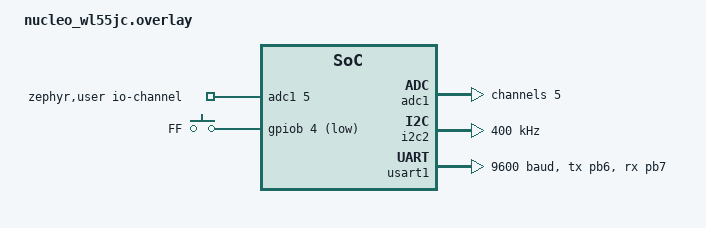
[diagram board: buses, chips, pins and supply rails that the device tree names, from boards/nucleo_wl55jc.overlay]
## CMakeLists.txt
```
# SPDX-License-Identifier: Apache-2.0

cmake_minimum_required(VERSION 3.20.0)
find_package(Zephyr REQUIRED HINTS $ENV{ZEPHYR_BASE})
project(MultiSensorPPE)

FILE(GLOB app_sources src/*.c)
target_sources(app PRIVATE ${app_sources})
```

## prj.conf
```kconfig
# General system configuration
CONFIG_MAIN_STACK_SIZE=2048
CONFIG_SYSTEM_WORKQUEUE_STACK_SIZE=2048
CONFIG_ASSERT=y
CONFIG_THREAD_NAME=y

# Logging and debugging
CONFIG_LOG=y
CONFIG_LOG_DEFAULT_LEVEL=3
CONFIG_STDOUT_CONSOLE=y
CONFIG_CBPRINTF_FP_SUPPORT=y

# Device drivers
CONFIG_GPIO=y
CONFIG_ADC=y
CONFIG_I2C=y
CONFIG_SENSOR=y
CONFIG_FLASH=y
CONFIG_FLASH_MAP=y
CONFIG_FLASH_PAGE_LAYOUT=y
CONFIG_STREAM_FLASH=y
CONFIG_IMG_MANAGER=y

# UART configuration
CONFIG_UART_ASYNC_API=y
CONFIG_UART_INTERRUPT_DRIVEN=y

# LoRa and LoRaWAN configuration
CONFIG_LORA=y
CONFIG_LORAWAN=y
CONFIG_LORAMAC_REGION_EU868=y
CONFIG_LORAWAN_NVM_SETTINGS=y  # Use NVM to store OTAA parameters
CONFIG_ENTROPY_GENERATOR=y  # Entropy source

# Non-volatile storage (NVS)
CONFIG_NVS=y
CONFIG_SETTINGS=y  # Required to store LoRaWAN DevNonce and other settings

# Zephyr Bus configuration
CONFIG_ZBUS=y
CONFIG_ZBUS_CHANNEL_NAME=y
```

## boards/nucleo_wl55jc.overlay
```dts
/*
 * SPDX-License-Identifier: Apache-2.0
 *
 * Copyright (c) 2022 QRTECH
 */

/ {
	zephyr,user {
		io-channels = <&adc1 5>;
	};

	gpio_keys {
		compatible = "gpio-keys";

		accel_interrup: adc_in1_pb4 {
			label = "FF";
			gpios = <&gpiob 4 (GPIO_ACTIVE_LOW | GPIO_PULL_UP)>;
			zephyr,code = <INPUT_KEY_3>;
		};
	};

	aliases {
		ff0 = &accel_interrup;
	};

};

&adc1 {
	#address-cells = <1>;
	#size-cells = <0>;

	channel@5 {
		reg = <5>;
		zephyr,gain = "ADC_GAIN_1";
		zephyr,reference = "ADC_REF_INTERNAL";
		zephyr,acquisition-time = <ADC_ACQ_TIME_DEFAULT>;
		zephyr,resolution = <12>;
	};
};

&i2c2 {
    status = "okay";
    clock-frequency = <I2C_BITRATE_FAST>; // 400kHz
};

&usart1 {
	dmas = <&dmamux1 11 18 (STM32_DMA_PERIPH_TX | STM32_DMA_PRIORITY_HIGH)
		&dmamux1 1 17 (STM32_DMA_PERIPH_RX | STM32_DMA_PRIORITY_HIGH)>;
	dma-names = "tx", "rx";
	pinctrl-0 = <&usart1_tx_pb6 &usart1_rx_pb7>;
	pinctrl-names = "default";
	current-speed = <9600>;
	status = "okay";
};

&dma1 {
	status = "okay";
};

&dma2 {
	status = "okay";
};

&dmamux1 {
	status = "okay";
};

&gpiob {
    status = "okay";
};
```

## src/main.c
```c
#include <zephyr/kernel.h>
#include <zephyr/device.h>
#include <zephyr/logging/log.h>
#include <zephyr/drivers/gpio.h>
#include <zephyr/sys/util.h>
#include <zephyr/sys/printk.h>
#include <inttypes.h>
#include <zephyr/sys/util_macro.h>
#include <zephyr/zbus/zbus.h>

#include "messages.h"
#include "gps_sensor.h"

LOG_MODULE_REGISTER(main, LOG_LEVEL_INF);

#define USART_NODE DT_NODELABEL(usart1)
#if !DT_NODE_HAS_STATUS_OKAY(USART_NODE)
#error "Unsupported board: usart1 devicetree node label is not defined"
#endif
#define FF_INT DT_ALIAS(ff0)
#if !DT_NODE_HAS_STATUS_OKAY(FF_INT)
#error "Unsupported board: ffpin devicetree alias is not defined"
#endif
#define SW0_NODE DT_ALIAS(sw1)
#if !DT_NODE_HAS_STATUS_OKAY(SW0_NODE)
#error "Unsupported board: sw1 devicetree alias is not defined"
#endif
#define SWSOS_NODE DT_ALIAS(sw2)
#if !DT_NODE_HAS_STATUS_OKAY(SWSOS_NODE)
#error "Unsupported board: sw2 devicetree alias is not defined"
#endif

#define PERIODIC_SENSOR_TIME    K_SECONDS(30)
#define LONG_PRESS_TIME    K_MSEC(2000)
#define SOS_LONG_PRESS_TIME    K_MSEC(1000)

ZBUS_CHAN_DECLARE(events_chan);
ZBUS_CHAN_DECLARE(sensor_data_chan);

static const struct device *usart_dev = DEVICE_DT_GET(USART_NODE);
static const struct gpio_dt_spec freefall = GPIO_DT_SPEC_GET_OR(FF_INT, gpios, {0});
static const struct gpio_dt_spec button = GPIO_DT_SPEC_GET_OR(SW0_NODE, gpios, {0});
static const struct gpio_dt_spec sos_button = GPIO_DT_SPEC_GET_OR(SWSOS_NODE, gpios, {0});
static struct gpio_callback freefall_cb_data;
static struct gpio_callback button_cb_data;
static struct gpio_callback sos_button_cb_data;

static uint8_t button_pressed = 0;
static uint8_t sos_button_pressed = 0;

struct events_wq_info {
	struct k_work work;
	const struct zbus_channel *chan;
	uint8_t handle;
};

static struct events_wq_info wq_button_event_handler = {.chan = &events_chan, .handle = 1};
static struct events_wq_info wq_sos_button_event_handler = {.chan = &events_chan, .handle = 2};
static struct events_wq_info wq_freefall_event_handler = {.chan = &events_chan, .handle = 3};
static struct events_wq_info wq_timer_event_handler = {.chan = &events_chan, .handle = 4};

void freefall_detect(const struct device *dev, struct gpio_callback *cb, uint32_t pins) {
    k_work_submit(&wq_freefall_event_handler.work);
}

void sos_button_timeout_handler(struct k_timer *timer_id) {
    if (sos_button_pressed) {
        sos_button_pressed = 0;
        k_work_submit(&wq_sos_button_event_handler.work);
    }
}

K_TIMER_DEFINE(sos_button_timer, sos_button_timeout_handler, NULL);

void sos_button_pressed_handler(const struct device *dev, struct gpio_callback *cb, uint32_t pins) {
    int val = gpio_pin_get(dev, sos_button.pin);

    if (val == 0) { // Button released
        sos_button_pressed = 0;
    } else { //Button Pressed
        sos_button_pressed = 1;
        k_timer_start(&sos_button_timer, SOS_LONG_PRESS_TIME, K_FOREVER);
    }
}

void button_timeout_handler(struct k_timer *timer_id) {
    if (button_pressed) {
        button_pressed = 0;
        k_work_submit(&wq_button_event_handler.work);
    }
} 

K_TIMER_DEFINE(button_timer, button_timeout_handler, NULL);

void button_pressed_handler(const struct device *dev, struct gpio_callback *cb, uint32_t pins) {
    int val = gpio_pin_get(dev, button.pin);

    if (val == 0) { // Button released
        button_pressed = 0;
    } else { //Button Pressed
        button_pressed = 1;
        k_timer_start(&button_timer, LONG_PRESS_TIME, K_FOREVER);
    }
}

static void wq_eh_cb(struct k_work *item)
{
	struct events_wq_info *sens = CONTAINER_OF(item, struct events_wq_info, work);
    uint8_t msg = sens->handle;
    zbus_chan_pub(&events_chan, &msg, K_MSEC(250));

	LOG_INF("Event_handler %u", sens->handle);
}

static void timer_cb (struct k_timer *timer_id) {
    k_work_submit(&wq_timer_event_handler.work);
}

K_TIMER_DEFINE(event_timer, timer_cb, NULL);

int main(void)
{

    if (!gpio_is_ready_dt(&button))
        LOG_ERR("Error button device is not ready");
    if (gpio_pin_configure_dt(&button, GPIO_INPUT))
        LOG_ERR("Error failed to configure pin");
    if (gpio_pin_interrupt_configure_dt(&button, GPIO_INT_EDGE_BOTH)) 
        LOG_ERR("Error failed to configure interrupt on pin");
    
    gpio_init_callback(&button_cb_data, button_pressed_handler, BIT(button.pin));
    gpio_add_callback(button.port, &button_cb_data);

    LOG_INF("Set up %s pin %d as Button Interuption Pin Succesfully", button.port->name, button.pin);

    if (!gpio_is_ready_dt(&sos_button))
        LOG_ERR("Error sos_button device is not ready");
    if (gpio_pin_configure_dt(&sos_button, GPIO_INPUT))
        LOG_ERR("Error failed to configure pin");
    if (gpio_pin_interrupt_configure_dt(&sos_button, GPIO_INT_EDGE_FALLING)) 
        LOG_ERR("Error failed to configure interrupt on pin");
    
    gpio_init_callback(&sos_button_cb_data, sos_button_pressed_handler, BIT(sos_button.pin));
    gpio_add_callback(sos_button.port, &sos_button_cb_data);

    LOG_INF("Set up %s pin %d as SOS Button Interuption Pin Succesfully", sos_button.port->name, sos_button.pin);

    if (!gpio_is_ready_dt(&freefall))
        LOG_ERR("Error freefall pin %s is not ready", freefall.port->name);
    if (gpio_pin_configure_dt(&freefall, GPIO_INPUT))
        LOG_ERR("Error failed to configure FREEFALL pin");
    if (gpio_pin_interrupt_configure_dt(&freefall, GPIO_INT_EDGE_FALLING))
        LOG_ERR("Error failed to configure interrupt on FREEFALL pin");

    gpio_init_callback(&freefall_cb_data, freefall_detect, BIT(freefall.pin));
    gpio_add_callback(freefall.port, &freefall_cb_data);

    LOG_INF("Set up %s pin %d as FreeFall Interruption Pin Succesfully", freefall.port->name, freefall.pin);

    usart1_capture(usart_dev);
    
    k_work_init(&wq_timer_event_handler.work, wq_eh_cb);
    k_work_init(&wq_freefall_event_handler.work, wq_eh_cb);
    k_work_init(&wq_button_event_handler.work, wq_eh_cb);
    k_work_init(&wq_sos_button_event_handler.work, wq_eh_cb);
    k_timer_start(&event_timer, PERIODIC_SENSOR_TIME, PERIODIC_SENSOR_TIME);

    return 0;
    
}
```

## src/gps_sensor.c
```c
#include <zephyr/kernel.h>
#include <zephyr/device.h>
#include <zephyr/drivers/uart.h>
#include <zephyr/logging/log.h>
#include <string.h>
#include <stdlib.h>

LOG_MODULE_REGISTER(gps_parser, LOG_LEVEL_INF); 

#define UART_BUFFER_SIZE 128
#define GPS_BUFFER_SIZE 80 

static const struct device *uart_dev;
static uint8_t recv_buffer[UART_BUFFER_SIZE];
static uint8_t gps_buffer[GPS_BUFFER_SIZE];
static size_t recv_index = 0;
static bool capturing = false;

static const char gpgga_prefix[] = "$GPGGA";
// Estructura para almacenar datos del GPS
typedef struct
{
    float latitude;
    char lat_dir; // N o S o M
    float longitude;
    char lon_dir; // E o O
    uint8_t fix_indicator; // 0 Fix no disponible 1 Fix 2 Diferential fix
    //int num_satellites;
    float altitude;
} gps_data_t;

static gps_data_t current_gps_data;

// Función para parsear sentencia GPGGA
void parse_gpgga(const char *nmea_sentence, gps_data_t *gps_data)
{
    char *token;
    char sentence_copy[UART_BUFFER_SIZE]; // Buffer copia auxiliar
    strncpy(sentence_copy, nmea_sentence, UART_BUFFER_SIZE - 1);
    sentence_copy[UART_BUFFER_SIZE - 1] = '\0'; // Fijamos valor final

    // Eliminar el checksum al final si está presente
    char *checksum_start = strchr(sentence_copy, '*');
    if (checksum_start)
    {
        *checksum_start = '\0';
    }

    // Omitir "$GPGGA" - Ignoramos
    token = strtok(sentence_copy, ","); // "$GPGGA"

    // 1. Time - Ignoramos
    token = strtok(NULL, ",");

    // 2. Latitud valor
    token = strtok(NULL, ",");
    if (token && strlen(token) > 0)
    {
        gps_data->latitude = atof(token);
    }
    else
    {
        gps_data->latitude = 0.0;
    }

    // 3. Latitud
    token = strtok(NULL, ",");
    if (token && strlen(token) > 0)
    {
        gps_data->lat_dir = token[0];
    }
    else
    {
        gps_data->lat_dir = ' ';
    }

    // 4. Longitud valor
    token = strtok(NULL, ",");
    if (token && strlen(token) > 0)
    {
        gps_data->longitude = atof(token);
    }
    else
    {
        gps_data->longitude = 0.0;
    }

    // 5. Longitud
    token = strtok(NULL, ",");
    if (token && strlen(token) > 0)
    {
        gps_data->lon_dir = token[0];
    }
    else
    {
        gps_data->lon_dir = ' ';
    }

    // 6. Fix Indicator
    token = strtok(NULL, ",");
    if (token && strlen(token) > 0)
    {
        gps_data->fix_indicator = atoi(token);
    }
    else
    {
        gps_data->fix_indicator = 0;
    }

    // 7. Number of Satellites - Ignoramos
    token = strtok(NULL, ",");
    

    // 8. HDOP - Ignoramos
    token = strtok(NULL, ",");

    // 9. Altitud
    token = strtok(NULL, ",");
    if (token && strlen(token) > 0)
    {
        gps_data->altitude = atof(token);
    }
    else
    {
        gps_data->altitude = 0.0;
    }
}

static void uart_cb(const struct device *dev, struct uart_event *evt, void *user_data)
{
    ARG_UNUSED(dev);
    ARG_UNUSED(user_data);

    switch (evt->type)
    {
        case UART_RX_RDY:
        for (int i = 0; i < evt->data.rx.len; i++)
        {
            char c = evt->data.rx.buf[evt->data.rx.offset + i];

            // Buscamos Inicio Sentencia %GPGGA
            if (!capturing)
            {
                // Desplazamiento de ventana para comparar con "$GPGGA"
                // Un pequeño buffer estático para detectar el prefijo
                static char window[6] = {0};
                for (int j = 0; j < 5; j++)
                {
                    window[j] = window[j + 1];
                }
                window[5] = c;

                if (strncmp(window, gpgga_prefix, 6) == 0)
                {
                    capturing = true;
                    recv_index = 0;
                    memcpy(gps_buffer, gpgga_prefix, 6);
                    recv_index = 6;
                }
            }
            else
            {
                // Captura $GPGGA hasta \n
                if (recv_index < UART_BUFFER_SIZE - 1)
                {
                    gps_buffer[recv_index++] = c;

                    if (c == '\n')
                    {
                        gps_buffer[recv_index] = '\0';

                        parse_gpgga((char *)gps_buffer, &current_gps_data);
                        capturing = false;
                        recv_index = 0;
                    }
                }
                else
                {
                    capturing = false;
                    recv_index = 0;
                }
            }
        }
        break;

    case UART_RX_DISABLED:
        memset(gps_buffer,0,GPS_BUFFER_SIZE);
        break;

    case UART_RX_BUF_REQUEST:
        uart_rx_buf_rsp(dev, gps_buffer, GPS_BUFFER_SIZE);
        break;
    default:
        break;
    }
}

int usart1_capture(const struct device *uart_dev)
{

    if (!device_is_ready(uart_dev))
    {
        LOG_ERR("UART device not ready");
        return -ENODEV;
    }

    uart_callback_set(uart_dev, uart_cb, NULL);

    int err = uart_rx_enable(uart_dev, recv_buffer, UART_BUFFER_SIZE, SYS_FOREVER_US);
    if (err)
    {
        LOG_ERR("Failed to enable UART RX: %d", err);
        return err;
    }

    LOG_INF("USART GPS listener succesfully started");

    current_gps_data.latitude = 0.0f;
    current_gps_data.lat_dir = " ";
    current_gps_data.longitude = 0.0f;
    current_gps_data.lon_dir = " ";
    current_gps_data.fix_indicator = 0;
    current_gps_data.altitude = 0.0f;
    return 0;
}

float readLatitude(void){ return current_gps_data.latitude; }
char readLatitudeDirection(void){ return current_gps_data.lat_dir; }
float readLongitude(void){ return current_gps_data.longitude; }
float readLLongitudeDirection(void){ return current_gps_data.lon_dir; }
uint8_t readFixIndicator(void){ return current_gps_data.fix_indicator; }
float readAltitude (void) { return current_gps_data.altitude; }
```

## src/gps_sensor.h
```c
#pragma once

#include <zephyr/device.h>

int usart1_capture(const struct device *uart_dev);
float readLatitude(void);
char readLatitudeDirection(void);
float readLongitude(void);
float readLLongitudeDirection(void);
uint8_t readFixIndicator(void);
float readAltitude (void);
```

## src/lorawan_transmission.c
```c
#include <zephyr/kernel.h>
#include <zephyr/device.h>
#include <zephyr/logging/log.h>
#include <zephyr/zbus/zbus.h>
#include <zephyr/lorawan/lorawan.h>

#include "messages.h"

#define LORAWAN_DEV_EUI			{ 0x8A, 0x39, 0x32, 0x35, 0x59, 0x37,\
					  0x91, 0x95 }
#define LORAWAN_JOIN_EUI		{ 0xAA, 0xBB, 0xCC, 0xDD, 0x00, 0x11,\
					  0x22, 0x33 }
#define LORAWAN_APP_KEY			{ 0x2B, 0x7E, 0x15, 0x16, 0x28, 0xAE,\
					  0xD2, 0xA6, 0xAB, 0xF7, 0x15, 0x88,\
					  0x09, 0xCF, 0x4F, 0x3E }

LOG_MODULE_REGISTER(lorawan_module, LOG_LEVEL_INF);

ZBUS_CHAN_DECLARE(payload_chan);

ZBUS_SUBSCRIBER_DEFINE(lora_sub, 8);

static void dl_callback(uint8_t port, uint8_t flags, int16_t rssi, int8_t snr, uint8_t len,
			const uint8_t *hex_data)
{
	LOG_INF("Port %d, Pending %d, RSSI %ddB, SNR %ddBm, Time %d", port,
		flags & LORAWAN_DATA_PENDING, rssi, snr, !!(flags & LORAWAN_TIME_UPDATED));
	if (hex_data) {
		LOG_HEXDUMP_INF(hex_data, len, "Payload: ");
	}
}

static void lorwan_datarate_changed(enum lorawan_datarate dr)
{
	uint8_t unused, max_size;

	lorawan_get_payload_sizes(&unused, &max_size);
	LOG_INF("New Datarate: DR_%d, Max Payload %d", dr, max_size);
}

void lorawan_thread (void) {
    const struct device *lora_dev;
	struct lorawan_join_config join_cfg;
	uint8_t dev_eui[] = LORAWAN_DEV_EUI;
	uint8_t join_eui[] = LORAWAN_JOIN_EUI;
	uint8_t app_key[] = LORAWAN_APP_KEY;
	int ret;

	struct lorawan_downlink_cb downlink_cb = {
		.port = LW_RECV_PORT_ANY,
		.cb = dl_callback
	};
    // ret = lorawan_set_region(LORAWAN_REGION_EU868);
	// if (ret < 0) {
	// 	LOG_ERR("lorawan_set_region failed: %d", ret);
	// 	return 0;
	// } else {
	// 	LOG_INF("Lorawan region set to LORAWAN_REGION_EU868");
	// }

    // ret = lorawan_start();
	// if (ret < 0) {
	// 	LOG_ERR("lorawan_start failed: %d", ret);
	// }

	// LOG_INF("Setting Class A device...");
	// if (lorawan_set_class(LORAWAN_CLASS_A) == 0) {
	// 	LOG_INF("Set class succesfull");
	// } else {
	// 	LOG_ERR("Fail in setting class a");
	// }

	lorawan_register_downlink_callback(&downlink_cb);
	lorawan_register_dr_changed_callback(lorwan_datarate_changed);
	
	join_cfg.mode = LORAWAN_ACT_OTAA;
	join_cfg.dev_eui = dev_eui;
	join_cfg.otaa.join_eui = join_eui;
	join_cfg.otaa.app_key = app_key;
	join_cfg.otaa.nwk_key = app_key;

	printf("\r\n DEV_EUI: ");
    for (int i = 0; i < sizeof(dev_eui); ++i) printf("%02x", dev_eui[i]);
    printf("\r\n APP_EUI: ");
    for (int i = 0; i < sizeof(join_eui); ++i) printf("%02x", join_eui[i]);
    printf("\r\n APP_KEY: ");
    for (int i = 0; i < sizeof(app_key); ++i) printf("%02x", app_key[i]);
    printf("\r\n");

    LOG_INF("Trying to join network over OTAA...");
     int err;
    // for (int attempt = 0; attempt < 3; attempt++) {
	//     LOG_INF("Join attempt %d", attempt + 1);
	//     err = lorawan_join(&join_cfg);
	//     if (err == 0) {
	// 	    LOG_INF("Join successful");
	// 	    break;
	//     }
	//     LOG_WRN("Join failed (err=%d), retrying in 5s...", err);
	//     k_sleep(K_SECONDS(5));
    // }

	// if (err < 0 ){
	// 	LOG_ERR("Not possible to join the network over OTAA");
	// }

    const struct zbus_channel *chan;

    while (!zbus_sub_wait(&lora_sub, &chan, K_FOREVER)) {
        struct payload_msg payload;
		zbus_chan_read(chan, &payload, K_MSEC(200));
        LOG_HEXDUMP_INF(&payload, sizeof(payload), "Payload sent: ");
        /* Send Payload Message*/
		// ret = lorawan_send(2, &payload, sizeof(payload), LORAWAN_MSG_UNCONFIRMED);
		// if (ret == -EAGAIN) {
		// 	LOG_ERR("lorawan_send failed: %d. Continuing...", ret);
		// }

		// if (ret < 0) {
		// 	LOG_ERR("lorawan_send failed: %d", ret);
		// }
		// if (ret == 0 ) {
		// 	LOG_INF("Data sent");
		// }
		k_sleep(K_SECONDS(18));
    }
}

K_THREAD_DEFINE(lorawan_thread_id, 2048, lorawan_thread, NULL, NULL, NULL, 4, 0, 0);
```

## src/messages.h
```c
#ifndef _MESSAGES_H_
#define _MESSAGES_H_
#include <stdint.h>

struct sensor_msg {
	int16_t ax;
	int16_t ay;
	int16_t az;
	int16_t gx;
	int16_t gy;
	int16_t gz;
	int16_t temp;
	float latitude;
	float longitude;
	float altitude;
	char latDir;
	char lonDir;
	uint16_t pulsiMeterValue;
	uint8_t fix_indicator;
	uint8_t ff_status;
	uint8_t sos_status;
	uint8_t sos_counter;
};

struct payload_msg {
	uint8_t flags;
	uint8_t pyld_alt1;
	uint8_t pyld_alt2;
	uint8_t pyld_alt3;
	int16_t pyld_ax;
	int16_t pyld_ay;
	int16_t pyld_az;
	int16_t pyld_gx;
	int16_t pyld_gy;
	int16_t pyld_gz;
	int16_t pyld_temp;
	int16_t pyld_pulsimeter;
	float pyld_lat;
	float pyld_lon;
	
	
	
};

#endif /* _MESSAGES_H_ */
```

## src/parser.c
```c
#include "messages.h"

#include <stdint.h>

#include <zephyr/kernel.h>
#include <zephyr/logging/log.h>
#include <zephyr/sys/util_macro.h>
#include <zephyr/zbus/zbus.h>

LOG_MODULE_REGISTER(parser_module, LOG_LEVEL_INF);

ZBUS_CHAN_DEFINE(payload_chan,          /* Name */
                 struct payload_msg,              /* Message type */
                 NULL,                 /* Validator */
                 NULL,                 /* User data */
                 ZBUS_OBSERVERS(lora_sub), /* observers */
                 ZBUS_MSG_INIT(0)      /* Initial value 0*/
);

ZBUS_SUBSCRIBER_DEFINE(parser_sub, 4);
ZBUS_OBS_DECLARE(lora_sub);

static void parser_thread(void)
{
	const struct zbus_channel *chan;

	while (!zbus_sub_wait(&parser_sub, &chan, K_FOREVER)) {
		struct sensor_msg msg;

		zbus_chan_read(chan, &msg, K_MSEC(200));
        struct payload_msg payload;
        payload.flags = 0;
        if (msg.sos_status) {
            payload.flags = msg.sos_counter;
            payload.flags |= 0x80;
        }else {
            if (msg.ff_status) {
                payload.flags |= 0x40;
            }
            if (msg.fix_indicator) {
                payload.flags |= 0x20;
                if (msg.latDir == 'S') {
                    payload.flags |= 0x10;
                }
                if (msg.lonDir == 'W') {
                    payload.flags |= 0x08;
                }
            }

            LOG_INF("Fix: %d | FF: %d | SOS: %d",
                     msg.fix_indicator,
                     msg.ff_status,
                     msg.sos_status);
            LOG_INF("Accel Raw: ax=%d ay=%d az=%d", msg.ax, msg.ay, msg.az);
            LOG_INF("Gyro Raw:  gx=%d gy=%d gz=%d", msg.gx, msg.gy, msg.gz);
            LOG_INF("Temp Raw:  %d C", msg.temp);
            LOG_INF("GPS:   %.5f %c, %.5f %c, Alt: %.2f m",
                    msg.latitude, msg.latDir,
                    msg.longitude, msg.lonDir,
                    msg.altitude);
            LOG_INF("BPM Value: %d", msg.pulsiMeterValue);
            payload.pyld_ax = msg.ax;
            payload.pyld_ay = msg.ay;
            payload.pyld_az = msg.az;
            payload.pyld_gx = msg.gx;
            payload.pyld_gy =  msg.gy;
            payload.pyld_gz = msg.gz;
            payload.pyld_temp = msg.temp;
            payload.pyld_pulsimeter = msg.pulsiMeterValue;
            memcpy(&payload.pyld_lat, &msg.latitude, sizeof(float));
            memcpy(&payload.pyld_lon, &msg.longitude, sizeof(float));
            uint32_t alitude_int = msg.altitude*10;
            //uint32_t alitude_int = 12345;
            payload.pyld_alt1 = alitude_int >> 16;
            payload.pyld_alt2 = alitude_int >> 8;
            payload.pyld_alt3 = alitude_int;
        }

        zbus_chan_pub(&payload_chan, &payload, K_MSEC(250));
        
	}
}

K_THREAD_DEFINE(parser_thread_id, 512, parser_thread, NULL, NULL, NULL, 4, 0, 0);
```

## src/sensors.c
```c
#include <zephyr/logging/log.h>
#include <zephyr/zbus/zbus.h>
#include <zephyr/device.h>
#include <zephyr/devicetree.h>
#include <zephyr/drivers/adc.h>
#include <zephyr/drivers/gpio.h>
#include <zephyr/drivers/i2c.h>
#include "messages.h"
#include "gps_sensor.h"

#define I2C_NODE DT_NODELABEL(i2c2)
#if !DT_NODE_HAS_STATUS_OKAY(I2C_NODE)
#error "Unsupported board: i2c2 devicetree node label is not defined"
#endif

#define DT_SPEC_AND_COMMA(node_id, prop, idx) \
    ADC_DT_SPEC_GET_BY_IDX(node_id, idx),

#define BUTTON_EVENT    1
#define SOS_EVENT    2
#define FF_EVENT    3
#define SEN_EVENT    4

#define SENSOR_THREAD_PRIOR 5
#define MPU6050_ADDR 0x68
#define REG_CONFIG 0x1A
#define REG_ACCEL_CONFIG 0x1C
#define REG_GYRO_CONFIG 0x1B
#define REG_PWR_MGMT_1 0x6B
#define REG_ACCEL_XOUT_H 0x3B
#define REG_TEMP_OUT_H 0x41
#define REG_GYRO_XOUT_H 0x43

#define MMA8451_ADDR 0x1D // Dirección I2C del MMA8451 (7 bits)
#define MMA8451_REG_WHO_AM_I 0x0D
#define MMA8451_WHO_AM_I_VAL 0x1A // Valor esperado
#define REG_CTRL_REG_1 0x2A
#define REG_CTRL_REG_2 0x2B
#define XYZ_DATA_CFG_REG 0x0E
#define REG_OUT_X_MSB 0x01 // 0x01 para X MSB
#define SENSITIVITY_8G 0x02
#define SENSITIVITY_8G_VALUE 1024
#define ACCELEROMETER_F_SETUP 0x09
#define PL_CFG_REG 0x11
#define SYSMOD_REGISTER 0x0B

// Nuevos define
#define PULSE_CFG 0x21
#define PULSE_THSX 0x23
#define PULSE_THSY 0x24
#define PULSE_THSZ 0x25
#define PULSE_TMLT 0x26
#define PULSE_LTCY 0x27

#define FF_MT_CFG 0x15
#define FF_MT_SRC 0x16
#define FF_MT_THS 0x17
#define FF_MT_COUNT 0x18

#define INT_SOURCE 0x0C

#define CTRL_REG4 0x2D
#define CTRL_REG5 0x2E

// Sensibilidad 8g
#define SENSITIVITY_8G 0x02

typedef enum {NORMAL_MODE, LP_MODE, SOS_MODE} t_state;

LOG_MODULE_REGISTER(sensors_module, LOG_LEVEL_INF);

static const struct device *i2c_dev = DEVICE_DT_GET(I2C_NODE);
static struct gpio_dt_spec led = GPIO_DT_SPEC_GET_OR(DT_ALIAS(led0), gpios, {0});
static struct gpio_dt_spec sos_led = GPIO_DT_SPEC_GET_OR(DT_NODELABEL(blue_led_1), gpios, {0});

static uint8_t generate_payload = 0;
t_state state = NORMAL_MODE;
static uint16_t bpm_value = 0;

//Get Specs from DT
static const struct adc_dt_spec adc_channels[] = {
    DT_FOREACH_PROP_ELEM(DT_PATH(zephyr_user), io_channels, DT_SPEC_AND_COMMA)
};

static int write_register(const struct device *i2c_dev,uint8_t addr, uint8_t reg, uint8_t value) {
    uint8_t buf[2] = {reg, value};
    return i2c_write(i2c_dev, buf, 2, addr);
}

static int read_register(const struct device *i2c_dev, uint8_t addr, uint8_t reg, uint8_t *data, size_t len) {
    return i2c_write_read(i2c_dev, addr, &reg, 1, data, len);
}

static int8_t mpu6050_init(const struct device *i2c_dev) {
    if (!device_is_ready(i2c_dev)) {
        return -ENODEV;
    }
    write_register(i2c_dev, MPU6050_ADDR, REG_CONFIG, 0x03);
    write_register(i2c_dev, MPU6050_ADDR, REG_ACCEL_CONFIG, 0x08);
    write_register(i2c_dev, MPU6050_ADDR, REG_GYRO_CONFIG, 0x08);
    write_register(i2c_dev, MPU6050_ADDR, REG_PWR_MGMT_1, 0x00);
    return 0;
}

static int8_t mpu6050_read_accel(const struct device *i2c_dev, int16_t *ax, int16_t *ay, int16_t *az) {
    uint8_t buf[6];
    if (read_register(i2c_dev, MPU6050_ADDR, REG_ACCEL_XOUT_H, buf, 6) != 0) return -EIO;

    *ax = (int16_t)((buf[0] << 8) | buf[1]);
    *ay = (int16_t)((buf[2] << 8) | buf[3]);
    *az = (int16_t)((buf[4] << 8) | buf[5]);
    return 0;
}

static int8_t mpu6050_read_gyro(const struct device *i2c_dev, int16_t *gx, int16_t *gy, int16_t *gz) {
    uint8_t buf[6];
    if (read_register(i2c_dev, MPU6050_ADDR, REG_GYRO_XOUT_H, buf, 6) != 0) return -EIO;

    *gx = (int16_t)((buf[0] << 8) | buf[1]);
    *gy = (int16_t)((buf[2] << 8) | buf[3]);
    *gz = (int16_t)((buf[4] << 8) | buf[5]);
    return 0;
}

static int8_t mpu6050_read_temperature(const struct device *i2c_dev, int16_t *temp_c) {
    uint8_t buf[2];
    if (read_register(i2c_dev, MPU6050_ADDR, REG_TEMP_OUT_H, buf, 2) != 0) return -EIO;

    *temp_c = (int16_t)((buf[0] << 8) | buf[1]);
    return 0;
}


static int8_t mma8451_init(const struct device *i2c_dev) {
    if (!device_is_ready(i2c_dev)) {
        return -ENODEV;
    }
    //Reset
    uint8_t resetStatus = write_register(i2c_dev,MMA8451_ADDR, REG_CTRL_REG_2, 0x40);
    k_sleep(K_MSEC(5));// Espera para el reset
    //Inactive
    write_register(i2c_dev,MMA8451_ADDR, REG_CTRL_REG_1, 0x20);
    //Activamos flag FF Detection
    write_register(i2c_dev,MMA8451_ADDR, FF_MT_CFG, 0xB8);
    //Definimos THreshold
    write_register(i2c_dev,MMA8451_ADDR, FF_MT_THS, 0x05); //0x0F g
    //Definimos Tiempos de debounce
    write_register(i2c_dev,MMA8451_ADDR, FF_MT_COUNT, 0x02);

    //Definimos latencia para la lectura del bit que se activa
    write_register(i2c_dev,MMA8451_ADDR, PULSE_LTCY, 0x09);
    //Habilitamos Interrupciones FF
    write_register(i2c_dev,MMA8451_ADDR, CTRL_REG4, 0x04);//Para solo FF 0x04 para FF y TAPS 0x0C
    //ruteamos a INT1
    write_register(i2c_dev,MMA8451_ADDR, CTRL_REG5, 0x0C);

    //Establecemos 8G
    write_register(i2c_dev,MMA8451_ADDR, XYZ_DATA_CFG_REG, 0x02);
    //Set Active
    uint8_t ctrl1Value = 0;
    read_register(i2c_dev, MMA8451_ADDR, REG_CTRL_REG_1, &ctrl1Value, 1);
    ctrl1Value|=0x01;
    write_register(i2c_dev,MMA8451_ADDR, REG_CTRL_REG_1, ctrl1Value);
    
    return 0;
}

static int8_t mma8451_read_accel(const struct device *i2c_dev, float *acc_x, float *acc_y, float *acc_z) {

    uint8_t ibuf[6] = {0, 0, 0, 0, 0, 0};
    uint8_t baseReg = REG_OUT_X_MSB;

    read_register(i2c_dev, MMA8451_ADDR, REG_OUT_X_MSB, &ibuf, 6);
    int16_t x_int = ((int16_t)(ibuf[0]<<8 | ibuf[1]))>>2;
    int16_t y_int = ((int16_t)(ibuf[2]<<8 | ibuf[3]))>>2;
    int16_t z_int = ((int16_t)(ibuf[4]<<8 | ibuf[5]))>>2;

    *acc_x = (float) x_int / SENSITIVITY_8G_VALUE * 9.81;
    *acc_y = (float) y_int / SENSITIVITY_8G_VALUE * 9.81;
    *acc_z = (float) (z_int) / SENSITIVITY_8G_VALUE * 9.81;
}
static uint8_t mma8451_read_freefall(const struct device *i2c_dev) {
    uint8_t intBufValue;
    read_register(i2c_dev, MMA8451_ADDR, INT_SOURCE, &intBufValue, 1);
    if (intBufValue & 0x04) {
        uint8_t ffBufValue;
        /*Lectura necesaria para hacer clear a bit EA y reiniciar deteccion*/
        read_register(i2c_dev, MMA8451_ADDR, FF_MT_SRC, &ffBufValue, 1);
        return 1;
    } else {
        return 0;
    }
    
}

uint8_t leds_init (void)  {
    if (!gpio_is_ready_dt(&led)) {
		LOG_ERR("Error LED device %s is not ready; ignoring it",led.port->name);
        return 0;
	}
    if (gpio_pin_configure_dt(&led, GPIO_OUTPUT)) {
        LOG_ERR("Error failed to configure LED device %s pin %d\n", led.port->name, led.pin);
        return 0;
    }
    if (!gpio_is_ready_dt(&sos_led)) {
		LOG_INF("Error SOS LED device %s is not ready; ignoring it\n", sos_led.port->name);
		return 0;
	}
    if (gpio_pin_configure_dt(&sos_led, GPIO_OUTPUT)) {
        LOG_INF("Error failed to configure SOS LED device %s pin %d\n", sos_led.port->name, sos_led.pin);
        return 0;
    }
    gpio_pin_set_dt(&sos_led, 1);
    gpio_pin_set_dt(&led, 0);
    LOG_INF("Leds ready");
    return 1;
}

static uint16_t read_adc_u16(uint16_t *raw_value) {
    if (!adc_is_ready_dt(&adc_channels[0])) {
        LOG_ERR("ADC no está listo");
        return -ENODEV;
    }

    int err = adc_channel_setup_dt(&adc_channels[0]);
    if (err < 0) {
        LOG_ERR("Fallo en la configuración del canal ADC (%d)", err);
        return err;
    }

    uint16_t buf;
    struct adc_sequence sequence = {
        .buffer = &buf,
        .buffer_size = sizeof(buf),
    };

    (void)adc_sequence_init_dt(&adc_channels[0], &sequence);

    err = adc_read_dt(&adc_channels[0], &sequence);
    if (err < 0) {
        LOG_ERR("Error en lectura ADC (%d)", err);
        return err;
    }

    *raw_value = buf;
    //Para obtener el valor en mv
    //int32_t val = adc_channels[0].channel_cfg.differential ? (int16_t)buf : buf;

    return 0;
}

ZBUS_CHAN_DEFINE(events_chan,          /* Name */
                 uint8_t,              /* Message type */
                 NULL,                 /* Validator */
                 NULL,                 /* User data */
                 ZBUS_OBSERVERS(sensor_sub), /* observers */
                 ZBUS_MSG_INIT(0)      /* Initial value 0*/
);

ZBUS_CHAN_DEFINE(sensor_data_chan,          /* Name */
                 struct sensor_msg,              /* Message type */
                 NULL,                 /* Validator */
                 NULL,                 /* User data */
                 ZBUS_OBSERVERS(parser_sub), /* observers */
                 ZBUS_MSG_INIT(0)      /* Initial value 0*/
);

ZBUS_SUBSCRIBER_DEFINE(sensor_sub, 8);
ZBUS_OBS_DECLARE(parser_sub);


void sensors_th(void) {
    LOG_INF("Getting sensors ready...");
    if (mpu6050_init(i2c_dev))
        LOG_ERR("MPU6050 device NOT configured");
    if (mma8451_init(i2c_dev))
        LOG_ERR("MMA8451 device NOT configured");
    leds_init();

    LOG_INF("");

	const struct zbus_channel *chan;
    t_state prev_state = NORMAL_MODE;
    uint8_t sos_counter = 0;
    struct sensor_msg sm = {0};

	while (!zbus_sub_wait(&sensor_sub, &chan, K_FOREVER)) {
        uint8_t event_msg;
        zbus_chan_read(chan, &event_msg, K_MSEC(250));
        switch (event_msg) {
        case BUTTON_EVENT:
            LOG_INF("BUTTON_EVENT");
                if (state == NORMAL_MODE) {
                    gpio_pin_set_dt(&sos_led, 0);
                    gpio_pin_set_dt(&led, 1);
                    state = LP_MODE;
                } else {
                    gpio_pin_set_dt(&sos_led, 1);
                    gpio_pin_set_dt(&led, 0);
                    state = NORMAL_MODE;
                } 
            break;
        case SOS_EVENT:
            LOG_INF("SOS_EVENT");
                if (state != SOS_MODE)
                    prev_state = state;
                state = SOS_MODE;
                sos_counter = 0;
                generate_payload = 1;
                sm.sos_status = 1;
                sm.sos_counter = sos_counter;
            break;
        case FF_EVENT:
            LOG_INF("FF_EVENT");
            if (mma8451_read_freefall(i2c_dev)){
                generate_payload = 1;
                sm.ff_status = 1;
            }
                
            break;
        case SEN_EVENT:
            LOG_INF("SEN_EVENT");
            switch (state) {
            case NORMAL_MODE:
                generate_payload = 1;
                mpu6050_read_accel(i2c_dev, &sm.ax, &sm.ay, &sm.az);
                mpu6050_read_gyro(i2c_dev, &sm.gx, &sm.gy, &sm.gz);
                mpu6050_read_temperature(i2c_dev, &sm.temp);
                sm.pulsiMeterValue = bpm_value;
                sm.latitude = readLatitude();
                sm.latDir = readLatitudeDirection();
                sm.longitude = readLongitude();
                sm.lonDir = readLLongitudeDirection();
                sm.fix_indicator = readFixIndicator();
                sm.altitude = readAltitude();
                sm.ff_status = 0;
                sm.sos_status = 0;
                break;
            case LP_MODE:
                generate_payload = 1;
                sm.ax, sm.ay, sm.az = 0;
                sm.gx, sm.gy, sm.gz = 0;
                sm.temp = 0;
                sm.pulsiMeterValue = 0;
                sm.latitude = readLatitude();
                sm.latDir = readLatitudeDirection();
                sm.longitude = readLongitude();
                sm.lonDir = readLLongitudeDirection();
                sm.fix_indicator = readFixIndicator();
                sm.altitude = readAltitude();
                sm.ff_status = 0;
                sm.sos_status = 0;
                break;
            case SOS_MODE:
                sos_counter ++;    
                if (sos_counter <= 3) {
                    generate_payload = 1;
                    sm.sos_counter = sos_counter;
                } else {
                    state = prev_state;
                }
                break;
            
            default:
                break;
            }
            break;
        default:
            LOG_INF("DEFAULT");
            break;
        }
        if (generate_payload) {
            generate_payload = 0;
            zbus_chan_pub(&sensor_data_chan, &sm, K_MSEC(250));
        }
		
		
	}
}

K_THREAD_DEFINE(sensors_th_id, 2024, sensors_th, NULL, NULL, NULL, 3, 0, 0);

void bpm_detection_thread(void) {
    uint32_t now;
    uint8_t bpm_measurement_counter = 0;
    uint8_t beats_counter = 0;
    while (1) {
        if (state == NORMAL_MODE) {
            uint16_t adc_val;
            if (read_adc_u16(&adc_val) == 0) {
                if (adc_val > 3500){
                    beats_counter++;
                    //LOG_INF("Heartbeat Detected - %d",adc_val);
                }
            }
            bpm_measurement_counter++;
            if (bpm_measurement_counter == 120) {
                bpm_value = beats_counter * 2;
                bpm_measurement_counter = 0;
                beats_counter = 0;
                //LOG_INF("BPM: %d", bpm_value);
            }
        }
        k_sleep(K_MSEC(250));
    }
}

#define STACK_SIZE 1024
#define THREAD_PRIORITY 5

K_THREAD_DEFINE(bpm_tid, STACK_SIZE, bpm_detection_thread, NULL, NULL, NULL, THREAD_PRIORITY, 0, 0);
```
